# ipro7 register map
Vendor: intelpro; Series: BTBLE
CPU: ipro7, little endian
Registers are 32-bit, read-write, reset 0x0 unless marked. A register's access mark holds for its fields unless they carry their own. Offsets are from the block's base; [hi:lo] are bit positions.

## CCI
Base 0x30009000
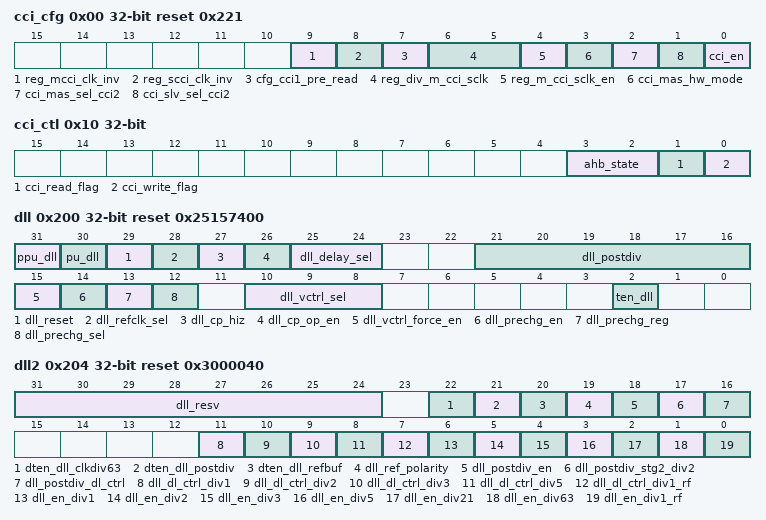
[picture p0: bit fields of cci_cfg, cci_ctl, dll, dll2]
0x00 cci_cfg reset 0x221
  [9] reg_mcci_clk_inv — 1: Invert MCCI Clk Out 0: No Invert MCCI Clk Out
  [8] reg_scci_clk_inv — 1 : Invert SCCI CLK IN 0 : No Invert SCCI CLK IN
  [7] cfg_cci1_pre_read — Set 1 to let CCI1 issue AHB Read immediately after address phase to save timing
  [6:5] reg_div_m_cci_sclk — CCI Master Port Clock Divier ( Freq of HCLK / N+1)
  [4] reg_m_cci_sclk_en — CCI Master Port Clock Out Control
  [3] cci_mas_hw_mode — CCI Master Port controlled by : 0 : APB Mode, 1: HW Mode
  [2] cci_mas_sel_cci2 — CCI Master Out Select ( 0: CCI1, 1: CCI2)
  [1] cci_slv_sel_cci2 — CCI Slave Out Select ( 0: CCI1, 1: CCI2)
  [0] cci_en — Enable CCI
0x04 cci_addr
  [31:0] apb_cci_addr — Address Control for CCI Master Port (APB Mode)
0x08 cci_wdata
  [31:0] apb_cci_wdata — Write data to CCI Master Port (APB Mode)
0x0C cci_rdata reset not defined
  [31:0] apb_cci_rdata ro — Read data from CCI Master Port (APB Mode)
0x10 cci_ctl (reset mask 0xFFFFFFF0)
  [3:2] ahb_state ro — AHB Bus Info
  [1] cci_read_flag ro — Write 1 to trigger CCI read
  [0] cci_write_flag ro — Write 1 to trigger CCI write
0x200 dll reset 0x25157400
  [31] ppu_dll
  [30] pu_dll
  [29] dll_reset
  [28] dll_refclk_sel — 0: xtal_hf, 1:rc32M
  [27] dll_cp_hiz — analog, set cp to high-z
  [26] dll_cp_op_en — analog, cp current steer branch vmid
  [25:24] dll_delay_sel — analog, 1->128M, 0->96M(debug only)
  [21:16] dll_postdiv — analog, dividing ratio for dll_clk_mmdiv output
  [15] dll_vctrl_force_en — analog, force vctrl
  [14] dll_prechg_en — analog, 1->prechg, don't use 0
  [13] dll_prechg_reg — analog
  [12] dll_prechg_sel — 1: use ppu/pu to generate pre-charge, 0: use dll_prechg_reg to generate pre-charge
  [10:8] dll_vctrl_sel — analog
  [2] ten_dll — analog, dc test enable
0x204 dll2 reset 0x3000040
  [31:24] dll_resv — analog, reserve
  [22] dten_dll_clkdiv63 — analog, digital test enable
  [21] dten_dll_postdiv — analog, digital test enable
  [20] dten_dll_refbuf — analog, digital test enable
  [19] dll_ref_polarity — analog, reference clock polarity
  [18] dll_postdiv_en — analog, postdiv enable
  [17] dll_postdiv_stg2_div2 — analog
  [16] dll_postdiv_dl_ctrl — analog
  [11] dll_dl_ctrl_div1 — analog, drive level of div1
  [10] dll_dl_ctrl_div2 — analog, drive level of div2
  [9] dll_dl_ctrl_div3 — analog, drive level of div3
  [8] dll_dl_ctrl_div5 — analog, drive level of div5
  [7] dll_dl_ctrl_div1_rf — analog, drive level of div1_rf
  [6] dll_en_div1 — enable of div1(128M), 50% dutycycle
  [5] dll_en_div2 — enable of div2, 50% dutycycle
  [4] dll_en_div3 — enable of div3, 50% dutycycle
  [3] dll_en_div5 — enable of div5, 50% dutycycle
  [2] dll_en_div21 — enable of div21, 50% dutycycle, for audio
  [1] dll_en_div63 — enable of div63, 50% dutycycle, for audio
  [0] dll_en_div1_rf — analog
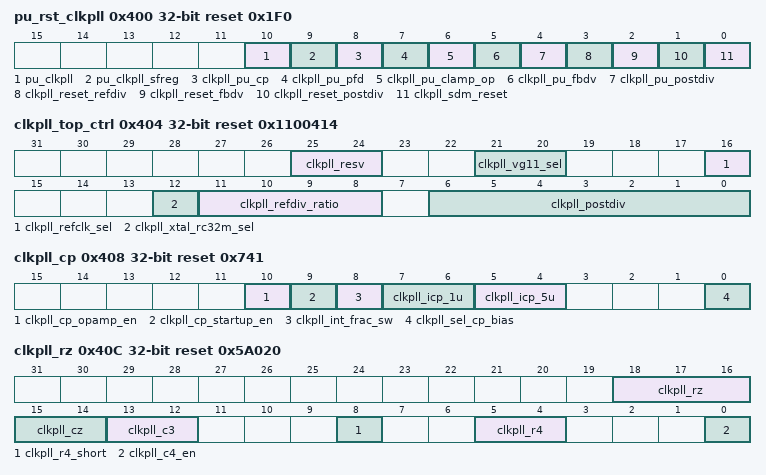
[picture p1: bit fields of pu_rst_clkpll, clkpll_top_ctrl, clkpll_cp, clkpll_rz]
0x400 pu_rst_clkpll reset 0x1F0
  [10] pu_clkpll — 1'b1: power up clock PLL
  [9] pu_clkpll_sfreg — 1'b1: power up clock PLL source follow regular
  [8] clkpll_pu_cp
  [7] clkpll_pu_pfd
  [6] clkpll_pu_clamp_op
  [5] clkpll_pu_fbdv
  [4] clkpll_pu_postdiv
  [3] clkpll_reset_refdiv
  [2] clkpll_reset_fbdv
  [1] clkpll_reset_postdiv
  [0] clkpll_sdm_reset
0x404 clkpll_top_ctrl reset 0x1100414
  [25:24] clkpll_resv
  [21:20] clkpll_vg11_sel — 0:1.05V; 1:1.1V; 2:1.15V; 3:1.2V
  [16] clkpll_refclk_sel — 0: rc32M or xtal32M; 1: xtal32M_soc
  [12] clkpll_xtal_rc32m_sel — 0:xtal; 1:rc32M
  [11:8] clkpll_refdiv_ratio
  [6:0] clkpll_postdiv — >=8 and should be even number
0x408 clkpll_cp reset 0x741
  [10] clkpll_cp_opamp_en
  [9] clkpll_cp_startup_en
  [8] clkpll_int_frac_sw — 0:int mode; 1:frac mode
  [7:6] clkpll_icp_1u — int mode:0; frac mode:1
  [5:4] clkpll_icp_5u — int mode:2; frac mode:0
  [0] clkpll_sel_cp_bias — 0:traditional cp; 1:clamp_op cp
0x40C clkpll_rz reset 0x5A020
  [18:16] clkpll_rz — int:1; frac:5
  [15:14] clkpll_cz — int:1; frac:2
  [13:12] clkpll_c3 — int:3; frac:2
  [8] clkpll_r4_short — int:1; frac:0
  [5:4] clkpll_r4 — int:2; frac:2
  [0] clkpll_c4_en — int:0; frac:0
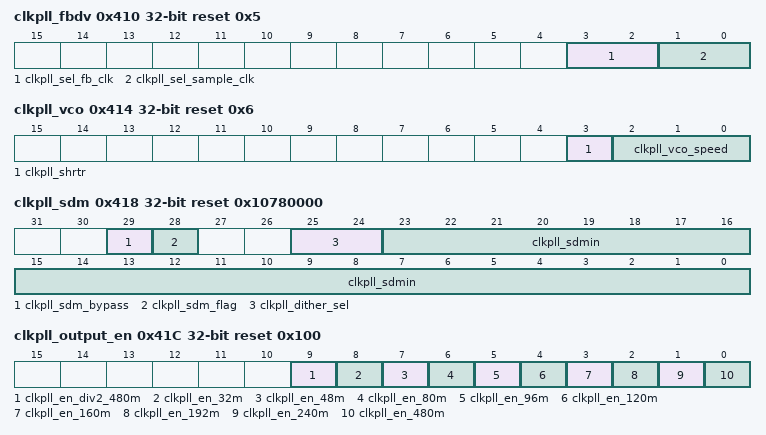
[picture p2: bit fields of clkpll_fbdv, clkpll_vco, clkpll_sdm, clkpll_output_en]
0x410 clkpll_fbdv reset 0x5
  [3:2] clkpll_sel_fb_clk — 0:mod1; 1:mod2; 2:mod3
  [1:0] clkpll_sel_sample_clk — 0:[16,63)mod3; 1:[32:127)mod4; 2:[64,255)mod5
0x414 clkpll_vco reset 0x6
  [3] clkpll_shrtr — noconn
  [2:0] clkpll_vco_speed
0x418 clkpll_sdm reset 0x10780000
  [29] clkpll_sdm_bypass — 1:bypass sdm
  [28] clkpll_sdm_flag — 1:sdm valid
  [25:24] clkpll_dither_sel
  [23:0] clkpll_sdmin — U(23,17), vco = refclk * clkpll_refdiv_ratio / (clkpll_sdmin>>17)
0x41C clkpll_output_en reset 0x100
  [9] clkpll_en_div2_480m, [8] clkpll_en_32m, [7] clkpll_en_48m, [6] clkpll_en_80m, [5] clkpll_en_96m, [4] clkpll_en_120m, [3] clkpll_en_160m, [2] clkpll_en_192m, [1] clkpll_en_240m, [0] clkpll_en_480m
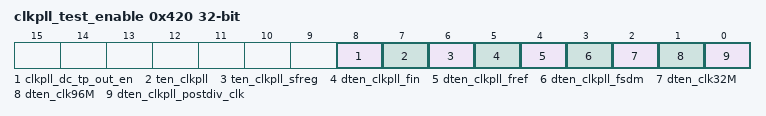
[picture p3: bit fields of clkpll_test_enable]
0x420 clkpll_test_enable
  [8] clkpll_dc_tp_out_en, [7] ten_clkpll, [6] ten_clkpll_sfreg, [5] dten_clkpll_fin, [4] dten_clkpll_fref, [3] dten_clkpll_fsdm, [2] dten_clk32M, [1] dten_clk96M, [0] dten_clkpll_postdiv_clk
